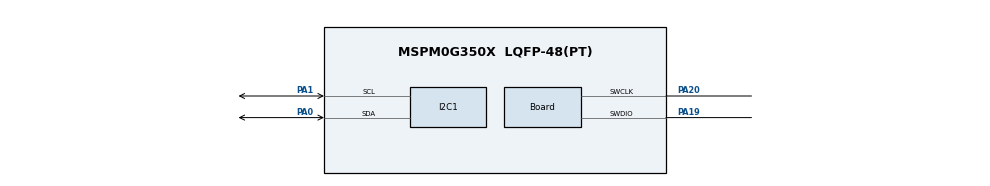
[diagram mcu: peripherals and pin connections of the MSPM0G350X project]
/**
 * @cliArgs --device "MSPM0G350X" --package "LQFP-48(PT)" --part "Default" --product "mspm0_sdk@2.01.00.03"
 * @versions {"tool":"1.20.0+3587"}
 */

/**
 * Import the modules used in this configuration.
 */
const I2C           = scripting.addModule("/ti/driverlib/I2C", {}, false);
const I2C1          = I2C.addInstance();
const SYSCTL        = scripting.addModule("/ti/driverlib/SYSCTL");
const ProjectConfig = scripting.addModule("/ti/project_config/ProjectConfig");

/**
 * Write custom configuration values to the imported modules.
 */
I2C1.$name                             = "I2C_OLED";
I2C1.basicEnableController             = true;
I2C1.basicControllerStandardBusSpeed   = "FastPlus";
I2C1.basicControllerBusSpeed           = 1600000;
I2C1.peripheral.$assign                = "I2C0";
I2C1.peripheral.sdaPin.$assign         = "PA0";
I2C1.peripheral.sclPin.$assign         = "PA1";
I2C1.sdaPinConfig.$name                = "ti_driverlib_gpio_GPIOPinGeneric0";
I2C1.sdaPinConfig.hideOutputInversion  = scripting.forceWrite(false);
I2C1.sdaPinConfig.onlyInternalResistor = scripting.forceWrite(false);
I2C1.sdaPinConfig.passedPeripheralType = scripting.forceWrite("Digital");
I2C1.sclPinConfig.$name                = "ti_driverlib_gpio_GPIOPinGeneric1";
I2C1.sclPinConfig.hideOutputInversion  = scripting.forceWrite(false);
I2C1.sclPinConfig.onlyInternalResistor = scripting.forceWrite(false);
I2C1.sclPinConfig.passedPeripheralType = scripting.forceWrite("Digital");

const Board                       = scripting.addModule("/ti/driverlib/Board", {}, false);
Board.peripheral.$assign          = "DEBUGSS";
Board.peripheral.swclkPin.$assign = "PA20";
Board.peripheral.swdioPin.$assign = "PA19";

SYSCTL.forceDefaultClkConfig = true;
SYSCTL.peripheral.$assign    = "SYSCTL";

ProjectConfig.deviceSpin = "MSPM0G3507";
scripting.suppress("Migrating requires going through the Switch Board or Device menu in the Device View section\\.", ProjectConfig, "deviceSpin");
